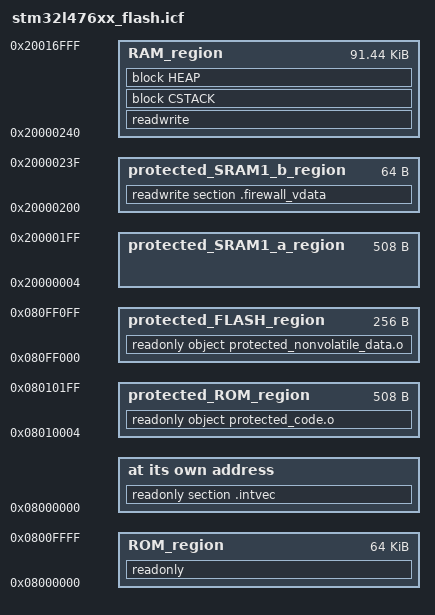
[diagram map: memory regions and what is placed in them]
/*###ICF### Section handled by ICF editor, don't touch! ****/
/*-Editor annotation file-*/
/* IcfEditorFile="$TOOLKIT_DIR$\config\ide\IcfEditor\cortex_v1_0.xml" */
/*-Specials-*/
define symbol __ICFEDIT_intvec_start__ = 0x08000000;
/*-Memory Regions-*/
define symbol __ICFEDIT_region_ROM_start__    = 0x08000000;
define symbol __ICFEDIT_region_ROM_end__      = 0x0800FFFF;
define symbol __ICFEDIT_region_RAM_start__    = 0x20000240;
define symbol __ICFEDIT_region_RAM_end__      = 0x20016FFF;

/*-Sizes-*/
define symbol __ICFEDIT_size_cstack__ = 0x400;
define symbol __ICFEDIT_size_heap__   = 0x200;
/**** End of ICF editor section. ###ICF###*/


/******************************************************************************/
/*                                                                            */
/*        protected_ROM: used to locate code in protected code segment        */
/*                                                                            */
/******************************************************************************/
/* Note that the protected code segment doesn't exactly start at the 
   starting address used to configure de Firewall.
   This allows to locate the function used to open the Firewall at the
   correct address to obey the call gate sequence */
define symbol __ICFEDIT_protected_region_ROM_start__    = 0x08010004;
define symbol __ICFEDIT_protected_region_ROM_end__      = 0x080101FF;


/******************************************************************************/
/*                                                                            */
/*           protected_FLASH: used to locate data in protected                */
/*                     non-volatile data segment                              */
/*                                                                            */
/******************************************************************************/
define symbol __ICFEDIT_protected_region_FLASH_start__    = 0x080FF000;
define symbol __ICFEDIT_protected_region_FLASH_end__      = 0x080FF0FF;


/******************************************************************************/
/*                                                                            */
/*    protected_SRAM1_a and protected_SRAM1_b: used to locate data in         */
/*                  protected non-volatile data segment                       */
/*                                                                            */
/******************************************************************************/
/* SRAM1 area protected by Firewall extends from 0x20000000
   to 0x2000023F. This area is divided in two sub-regions SRAM1_a
   and SRAM1_b to separate executable and non-executable volatile
   data for test purposes */
   
/*********************************************************************/
/*  SRAM1_a: used to locate executable code in volatile data segment */
/*  (not used in that example)                                       */
/*********************************************************************/
define symbol __ICFEDIT_protected_region_SRAM1_a_start__    = 0x20000004;
define symbol __ICFEDIT_protected_region_SRAM1_a_end__      = 0x200001FF;

/**********************************************************/
/*  SRAM1_b: used to locate data in volatile data segment */
/**********************************************************/
define symbol __ICFEDIT_protected_region_SRAM1_b_start__    = 0x20000200;
define symbol __ICFEDIT_protected_region_SRAM1_b_end__      = 0x2000023F;



/******************************************************************************/
/*                                                                            */
/*                            Regions definition                              */
/*                                                                            */
/******************************************************************************/
define memory mem with size = 4G;
define region ROM_region      = mem:[from __ICFEDIT_region_ROM_start__   to __ICFEDIT_region_ROM_end__];
define region protected_ROM_region      = mem:[from __ICFEDIT_protected_region_ROM_start__   to __ICFEDIT_protected_region_ROM_end__];
define region protected_FLASH_region    = mem:[from __ICFEDIT_protected_region_FLASH_start__   to __ICFEDIT_protected_region_FLASH_end__];
define region protected_SRAM1_a_region    = mem:[from __ICFEDIT_protected_region_SRAM1_a_start__   to __ICFEDIT_protected_region_SRAM1_a_end__];
define region protected_SRAM1_b_region    = mem:[from __ICFEDIT_protected_region_SRAM1_b_start__   to __ICFEDIT_protected_region_SRAM1_b_end__];
define region RAM_region      = mem:[from __ICFEDIT_region_RAM_start__   to __ICFEDIT_region_RAM_end__];

/******************************************/
/* place code to be protected by FIREWALL */
/******************************************/
place in  protected_ROM_region {readonly object protected_code.o};



define block CSTACK    with alignment = 8, size = __ICFEDIT_size_cstack__   { };
define block HEAP      with alignment = 8, size = __ICFEDIT_size_heap__     { };

define symbol __ICFEDIT_size_nvdata__   = 0x100;


initialize by copy { readwrite };
do not initialize  { section .noinit };
initialize by copy { section .firewall_vdata };

place at address mem:__ICFEDIT_intvec_start__ { readonly section .intvec };


place in ROM_region   { readonly };
place in RAM_region   { readwrite,
                        block CSTACK, block HEAP };                     

/*********************************************************************/                        
/* place non-volatile data in FLASH area to be protected by FIREWALL */
/*********************************************************************/ 
place in  protected_FLASH_region {readonly object protected_nonvolatile_data.o};


/******************************************************************************/  
/*         place volatile data in SRAM1 area (more specifically in            */
/*             SRAM1_b sub-region) to be protected by FIREWALL                */
/******************************************************************************/  
place in protected_SRAM1_b_region   {readwrite section .firewall_vdata };


